AUTOSAR XML (schema 4-0-3)
package /ComponentTypes
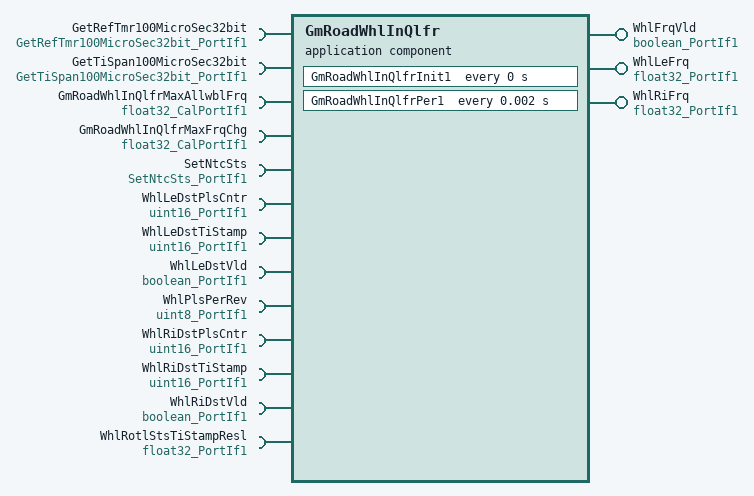
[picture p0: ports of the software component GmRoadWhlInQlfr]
  application sw component type GmRoadWhlInQlfr
    provide port WhlFrqVld: nonqueued-sender-com-spec{data-element=Logl, init-value=0}, provided-interface=boolean_PortIf1
    provide port WhlLeFrq: nonqueued-sender-com-spec{data-element=Val, init-value=0.01}, provided-interface=float32_PortIf1
    provide port WhlRiFrq: nonqueued-sender-com-spec{data-element=Val, init-value=0.01}, provided-interface=float32_PortIf1
    13 x require port:
      GetRefTmr100MicroSec32bit: required-interface=GetRefTmr100MicroSec32bit_PortIf1
      GetTiSpan100MicroSec32bit: required-interface=GetTiSpan100MicroSec32bit_PortIf1
      GmRoadWhlInQlfrMaxAllwblFrq: parameter-require-com-spec{init-value=55.48, parameter=Val}, required-interface=float32_CalPortIf1
      GmRoadWhlInQlfrMaxFrqChg: parameter-require-com-spec{init-value=1.5, parameter=Val}, required-interface=float32_CalPortIf1
      SetNtcSts: required-interface=SetNtcSts_PortIf1
      WhlLeDstPlsCntr: nonqueued-receiver-com-spec{data-element=Val, filter=data-filter-type=ALWAYS, init-value=0}, required-interface=uint16_PortIf1
      WhlLeDstTiStamp: nonqueued-receiver-com-spec{data-element=Val, filter=data-filter-type=ALWAYS, init-value=0}, required-interface=uint16_PortIf1
      WhlLeDstVld: nonqueued-receiver-com-spec{data-element=Logl, filter=data-filter-type=ALWAYS, init-value=0}, required-interface=boolean_PortIf1
      WhlPlsPerRev: nonqueued-receiver-com-spec{data-element=Val, filter=data-filter-type=ALWAYS, init-value=1}, required-interface=uint8_PortIf1
      WhlRiDstPlsCntr: nonqueued-receiver-com-spec{data-element=Val, filter=data-filter-type=ALWAYS, init-value=0}, required-interface=uint16_PortIf1
      WhlRiDstTiStamp: nonqueued-receiver-com-spec{data-element=Val, filter=data-filter-type=ALWAYS, init-value=0}, required-interface=uint16_PortIf1
      WhlRiDstVld: nonqueued-receiver-com-spec{data-element=Logl, filter=data-filter-type=ALWAYS, init-value=0}, required-interface=boolean_PortIf1
      WhlRotlStsTiStampResl: nonqueued-receiver-com-spec{data-element=Val, filter=data-filter-type=ALWAYS, init-value=0.000000002}, required-interface=float32_PortIf1
    behavior GmRoadWhlInQlfr_InternalBehavior
      ar-typed-per-instance-memorys:
        20 x data, all with sw-calibration-access=READ-ONLY:
          dGmRoadWhlInQlfrLeDeltaPls: type=uint16
          dGmRoadWhlInQlfrLeDeltaTiStamp: type=uint16
          dGmRoadWhlInQlfrLeWhlFrqVld: type=boolean
          dGmRoadWhlInQlfrRawLeWhlFrq: type=float32
          dGmRoadWhlInQlfrRawRiWhlFrq: type=float32
          dGmRoadWhlInQlfrRiDeltaPls: type=uint16
          dGmRoadWhlInQlfrRiDeltaTiStamp: type=uint16
          dGmRoadWhlInQlfrRiWhlFrqVld: type=boolean
          PrevLeWhlFrq: type=float32
          PrevLeWhlFrqVld: type=boolean
          PrevRawLeWhlFrq: type=float32
          PrevRawRiWhlFrq: type=float32
          PrevRiWhlFrq: type=float32
          PrevRiWhlFrqVld: type=boolean
          PrevVldLeWhlDstPlsCntr: type=uint16
          PrevVldLeWhlDstTiStamp: type=uint16
          PrevVldRiWhlDstPlsCntr: type=uint16
          PrevVldRiWhlDstTiStamp: type=uint16
          PrevVldTiLeFrqChg: type=uint32
          PrevVldTiRiFrqChg: type=uint32
      timing event GmRoadWhlInQlfr_InitEvent: start-on-event=GmRoadWhlInQlfrInit1, period=0
      timing event TMT_GmRoadWhlInQlfrPer1: start-on-event=GmRoadWhlInQlfrPer1, period=0.002
      runnable GmRoadWhlInQlfrInit1
        sync call SC_SetNtcSts_Oper: operation=SetNtcSts.Oper, timeout=0
      runnable GmRoadWhlInQlfrPer1
        data-receive-point-by-arguments:
          8 x access:
            REC_WhlLeDstPlsCntr_Val: accessed-variable=WhlLeDstPlsCntr.Val
            REC_WhlLeDstTiStamp_Val: accessed-variable=WhlLeDstTiStamp.Val
            REC_WhlLeDstVld_Logl: accessed-variable=WhlLeDstVld.Logl
            REC_WhlPlsPerRev_Val: accessed-variable=WhlPlsPerRev.Val
            REC_WhlRiDstPlsCntr_Val: accessed-variable=WhlRiDstPlsCntr.Val
            REC_WhlRiDstTiStamp_Val: accessed-variable=WhlRiDstTiStamp.Val
            REC_WhlRiDstVld_Logl: accessed-variable=WhlRiDstVld.Logl
            REC_WhlRotlStsTiStampResl_Val: accessed-variable=WhlRotlStsTiStampResl.Val
        data-send-points:
          access SEND_WhlFrqVld_Logl: accessed-variable=WhlFrqVld.Logl
          access SEND_WhlLeFrq_Val: accessed-variable=WhlLeFrq.Val
          access SEND_WhlRiFrq_Val: accessed-variable=WhlRiFrq.Val
        sync call SC_GetRefTmr100MicroSec32bit_Oper: operation=GetRefTmr100MicroSec32bit.Oper, timeout=0
        sync call SC_GetTiSpan100MicroSec32bit_Oper: operation=GetTiSpan100MicroSec32bit.Oper, timeout=0
        sync call SC_SetNtcSts_Oper: operation=SetNtcSts.Oper, timeout=0
  swc implementation GmRoadWhlInQlfr_Implementation: behavior=GmRoadWhlInQlfr_InternalBehavior
    code-descriptors:
      code Default: artifact-descriptors=autosar-engineering-object={short-label=Default, category=SWSRC}
